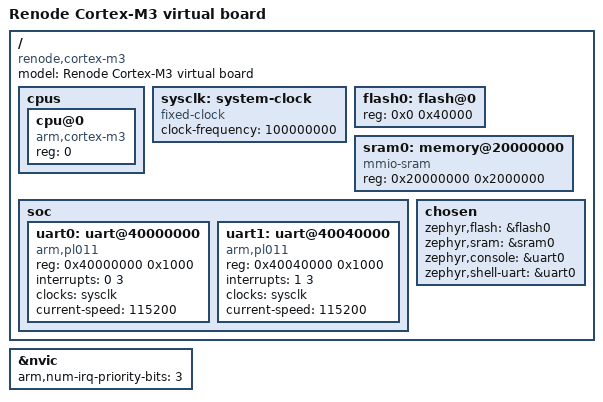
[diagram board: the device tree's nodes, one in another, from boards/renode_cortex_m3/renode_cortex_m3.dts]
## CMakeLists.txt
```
#
# Host application for the embedded80211 link protocol (Renode board profile).
#
# Runs on the app-local renode_cortex_m33 board (see boards/renode_cortex_m33/).
# uart1 is the bus port bridged to the device; uart0 is the console. The
# virtual Wi-Fi and BT HCI drivers are registered in app.overlay.
#
cmake_minimum_required(VERSION 3.20.5)
cmake_policy(SET CMP0057 NEW)

# Register the embedded80211 Zephyr module (sibling directory). Must be set
# before find_package(Zephyr) so the module is discovered during kernel-mode
# build configuration (mirrors nrf7002dk/CMakeLists.txt).
set(ZEPHYR_EXTRA_MODULES ${CMAKE_CURRENT_SOURCE_DIR}/../embedded80211)

# App-local board and SoC definitions. Prepend this directory to BOARD_ROOT
# and SOC_ROOT so `west build -b renode_cortex_m3` finds them without
# extra flags.
set(BOARD_ROOT ${CMAKE_CURRENT_SOURCE_DIR} ${BOARD_ROOT})
set(SOC_ROOT ${CMAKE_CURRENT_SOURCE_DIR} ${SOC_ROOT})

find_package(Zephyr REQUIRED HINTS $ENV{ZEPHYR_BASE})
project(e80211_host)
# Expose the embedded80211 module public headers to the app sources.
target_include_directories(app PUBLIC
	${CMAKE_CURRENT_SOURCE_DIR}/../embedded80211/zephyr/include
)

target_sources(app PRIVATE src/main.c)

if(CONFIG_HOST_TEST_ENABLED)
	target_sources(app PRIVATE src/e2e_test.c src/bt_e2e.c)
endif()
```

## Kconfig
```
source "Kconfig.zephyr"

# Host application options.
# The embedded80211 module Kconfig is sourced automatically when the module
# is registered via ZEPHYR_EXTRA_MODULES (see CMakeLists.txt).

# E2E test (disabled by default). When enabled, src/e2e_test.c is compiled in
# and e2e_test_start() is called from main(); WiFi credentials come from
# HOST_TEST_WIFI_SSID / HOST_TEST_WIFI_PSK (build-time, never committed).
config HOST_TEST_ENABLED
	bool "Enable end-to-end test"
	default n
	depends on EMBEDDED80211_HOST_WIFI
	depends on EMBEDDED80211_HOST_BT
config HOST_TEST_WIFI_SSID
	string "E2E test SSID (empty = skip WiFi E2E)"
	default ""

config HOST_TEST_WIFI_PSK
	string "E2E test PSK"
	default ""

config HOST_TEST_GATEWAY_PINGS
	int "Gateway ping count"
	default 4
```

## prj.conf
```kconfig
# Role: host driver.
CONFIG_SERIAL_HOST_ROLE=y
CONFIG_SERIAL=y
CONFIG_UART_INTERRUPT_DRIVEN=y


# embedded80211 host drivers.
CONFIG_EMBEDDED80211_HOST_BUS=y
CONFIG_EMBEDDED80211_HOST_WIFI=y
CONFIG_EMBEDDED80211_HOST_BT=y

# Networking (virtual Wi-Fi).
CONFIG_NETWORKING=y
CONFIG_NET_L2_ETHERNET=y
CONFIG_NET_L2_WIFI_MGMT=y
CONFIG_NET_MGMT_EVENT=y
CONFIG_NET_MGMT_EVENT_INFO=y
CONFIG_WIFI=y
CONFIG_NET_IPV4=y
CONFIG_NET_DHCPV4=y
CONFIG_NET_DHCPV4_LOG_LEVEL_DBG=y
CONFIG_NET_UDP=y
CONFIG_NET_LOG=y
CONFIG_NET_BUF_RX_COUNT=256
CONFIG_NET_BUF_TX_COUNT=64
CONFIG_NET_PKT_RX_COUNT=128
CONFIG_NET_PKT_TX_COUNT=64
# Accept broadcast L2 frames with L3 dst not yet matching the interface
# broadcast (needed before DHCP assigns an address).
CONFIG_NET_L2_ETHERNET_ACCEPT_MISMATCH_L3_L2_ADDR=y
CONFIG_HEAP_MEM_POOL_SIZE=8192

# Bluetooth (virtual HCI).
CONFIG_BT=y
CONFIG_BT_HCI=y
CONFIG_BT_OBSERVER=y
CONFIG_BT_DEVICE_NAME="e80211-host"

# Logging / console.
CONFIG_LOG=y
CONFIG_CONSOLE=y

# The bus client's sync handshake (bus_open -> bus_sync) needs more than the
# 1024 B default main stack; a smaller stack overflows and faults at boot.
# 4096 and 8192 were both insufficient with the full net+BT subsystem;
# the init path (net_if + DHCP + BT controller) consumes ~8 KB of stack.
CONFIG_MAIN_STACK_SIZE=16384

# The network stack's RX processing (net_if_recv_data -> DHCP -> ARP) runs
# on the system workqueue; the default 1024 B overflows and stalls RX,
# exhausting the net_buf pool.
CONFIG_SYSTEM_WORKQUEUE_STACK_SIZE=4096

# CRC32C for the link-protocol integrity feature (bus.c / serial_frame_crc).
CONFIG_CRC=y
CONFIG_CRC32_C=y
```

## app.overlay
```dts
/ {
	chosen {
		zephyr,bt-hci = &bt_hci_virt;
		embedded80211,bus = &uart1;
	};

	virt_wifi: virt-wifi {
		compatible = "embedded80211,virt-wifi";
	};

	bt_hci_virt: bt-hci-virtual {
		compatible = "embedded80211,bt-hci-virtual";
	};
};

&uart1 {
	status = "okay";
	current-speed = <115200>;
};
```

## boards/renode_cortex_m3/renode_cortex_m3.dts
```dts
/*
 * Renode virtual Cortex-M3 board for the host application.
 *
 * The peripheral map must stay in sync with the Renode machine definition
 * in support/renode_cortex_m3.repl:
 *   ROM   256 KiB @ 0x0
 *   RAM   32 MiB @ 0x20000000
 *   CPU   Cortex-M3 @ 100 MHz (systick)
 *   uart0 console  arm,pl011 @ 0x40000000  IRQ 0
 *   uart1 bus      arm,pl011 @ 0x40040000  IRQ 1
 *
 * Code is linked into the 256 KiB `flash0` region at 0x0 (Renode `rom`);
 * data lives in the 32 MiB SRAM at 0x20000000.
 */

/dts-v1/;

#include <arm/armv7-m.dtsi>

/ {
	#address-cells = <1>;
	#size-cells = <1>;
	compatible = "renode,cortex-m3";
	model = "Renode Cortex-M3 virtual board";

	cpus {
		#address-cells = <1>;
		#size-cells = <0>;
		cpu@0 {
			device_type = "cpu";
			compatible = "arm,cortex-m3";
			reg = <0>;
		};
	};

	sysclk: system-clock {
		compatible = "fixed-clock";
		clock-frequency = <100000000>;
		#clock-cells = <0>;
	};

	/* Code segment: Renode maps a writable 256 KiB region at 0x0
	 * (rom in support/renode_cortex_m3.repl); `loadelf` populates it. */
	flash0: flash@0 {
		reg = <0x0 0x40000>;
	};

	sram0: memory@20000000 {
		compatible = "mmio-sram";
		reg = <0x20000000 0x2000000>;
	};

	soc {
		#address-cells = <1>;
		#size-cells = <1>;
		ranges;

		uart0: uart@40000000 {
			compatible = "arm,pl011";
			reg = <0x40000000 0x1000>;
			interrupts = <0 3>;
			interrupt-names = "uart";
			clocks = <&sysclk>;
		};

		uart1: uart@40040000 {
			compatible = "arm,pl011";
			reg = <0x40040000 0x1000>;
			interrupts = <1 3>;
			interrupt-names = "uart";
			clocks = <&sysclk>;
		};
	};

	chosen {
		zephyr,flash = &flash0;
		zephyr,sram = &sram0;
		zephyr,console = &uart0;
		zephyr,shell-uart = &uart0;
	};
};

&uart0 {
	status = "okay";
	current-speed = <115200>;
};

&uart1 {
	status = "okay";
	current-speed = <115200>;
};

&nvic {
	arm,num-irq-priority-bits = <3>;
};
```

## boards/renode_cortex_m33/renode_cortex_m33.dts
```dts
/*
 * Renode virtual Cortex-M33 board for the host application.
 *
 * The peripheral map must stay in sync with the Renode machine definition
 * in support/renode_cortex_m33.repl:
 *   ROM   256 KiB @ 0x0
 *   RAM   32 MiB @ 0x20000000
 *   CPU   Cortex-M33 @ 100 MHz (systick)
 *   uart0 console  arm,pl011 @ 0x40000000  IRQ 0
 *   uart1 bus      arm,pl011 @ 0x40040000  IRQ 1
 *
 * Code is linked into the 256 KiB `flash0` region at 0x0 (Renode `rom`);
 * data lives in the 32 MiB SRAM at 0x20000000.
 */

/dts-v1/;

#include <arm/armv8-m.dtsi>

/ {
	#address-cells = <1>;
	#size-cells = <1>;
	compatible = "renode,cortex-m33";
	model = "Renode Cortex-M33 virtual board";

	cpus {
		#address-cells = <1>;
		#size-cells = <0>;
		cpu@0 {
			device_type = "cpu";
			compatible = "arm,cortex-m33";
			reg = <0>;
		};
	};

	sysclk: system-clock {
		compatible = "fixed-clock";
		clock-frequency = <100000000>;
		#clock-cells = <0>;
	};


	/* Code segment: Renode maps a writable 256 KiB region at 0x0
	 * (rom in support/renode_cortex_m33.repl); `loadelf` populates it. */
	flash0: flash@0 {
		reg = <0x0 0x40000>;
	};

	sram0: memory@20000000 {
		compatible = "mmio-sram";
		reg = <0x20000000 0x2000000>;
	};

	soc {
		#address-cells = <1>;
		#size-cells = <1>;
		ranges;

		uart0: uart@40000000 {
			compatible = "arm,pl011";
			reg = <0x40000000 0x1000>;
			interrupts = <0 3>;
			interrupt-names = "uart";
			clocks = <&sysclk>;
		};

		uart1: uart@40040000 {
			compatible = "arm,pl011";
			reg = <0x40040000 0x1000>;
			interrupts = <1 3>;
			interrupt-names = "uart";
			clocks = <&sysclk>;
		};
	};

	chosen {
		zephyr,flash = &flash0;
		zephyr,sram = &sram0;
		zephyr,console = &uart0;
		zephyr,shell-uart = &uart0;
	};
};

&uart0 {
	status = "okay";
	current-speed = <115200>;
};

&uart1 {
	status = "okay";
	current-speed = <115200>;
};

&nvic {
	arm,num-irq-priority-bits = <3>;
};
```

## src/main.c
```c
/*
 * Host application entry point (Renode board profile).
 *
 * Boots the virtual Wi-Fi / BT HCI drivers (registered via app.overlay),
 * opens the link-protocol bus to the device, and starts the E2E test threads.
 */

#include <zephyr/kernel.h>
#include <zephyr/logging/log.h>

#include <embedded80211/bus.h>

#if CONFIG_HOST_TEST_ENABLED
#include "e2e_test.h"
#include "bt_e2e.h"
#endif

LOG_MODULE_REGISTER(e80211_host, LOG_LEVEL_INF);

int main(void)
{
	LOG_INF("e80211 host app booting");

	int rc = bus_open();

	if (rc != 0) {
		LOG_ERR("bus_open failed: %d", rc);
	} else {
		LOG_INF("bus synced: supported types 0x%04x",
			bus_supported_types());
	}

#if CONFIG_HOST_TEST_ENABLED
	e2e_test_start();
	bt_e2e_start();
#endif

	return 0;
}
```

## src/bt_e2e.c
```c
/*
 * E2E Bluetooth test for the host app.
 *
 * Periodic BLE scan window, logging discovered devices.
 *
 * Log marker (consumed by host/tests/run_e2e.sh):
 *   E2E BT:  SCAN DONE found=<n>
 */

#include <zephyr/kernel.h>
#include <zephyr/logging/log.h>
#include <zephyr/bluetooth/bluetooth.h>
#include <zephyr/bluetooth/addr.h>

#include "bt_e2e.h"
#include "e2e_test.h"

LOG_MODULE_REGISTER(e80211_e2e_bt, LOG_LEVEL_INF);

#define BT_SCAN_WINDOW_S  10U
#define BT_SCAN_PERIOD_S  30U

static int bt_found_count;

static void bt_adv_cb(const bt_addr_le_t *addr, int8_t rssi,
		      uint8_t adv_type, struct net_buf_simple *buf)
{
	char addr_str[BT_ADDR_LE_STR_LEN];

	bt_addr_le_to_str(addr, addr_str, sizeof(addr_str));
	bt_found_count++;
	LOG_INF("E2E BT: DEV %s rssi=%d", addr_str, rssi);
}

static const struct bt_le_scan_param scan_params[] = BT_LE_SCAN_ACTIVE;

static void bt_e2e_thread(void *p1, void *p2, void *p3)
{
	ARG_UNUSED(p1);
	ARG_UNUSED(p2);
	ARG_UNUSED(p3);
	/* Wait for the Wi-Fi connect phase to finish before touching the
	 * BT controller. The nRF7002 shares one IPC link for Wi-Fi and
	 * BT; concurrent HCI and Wi-Fi management commands cause HCI
	 * command timeouts and a fatal assertion. e2e_wait_wifi_phase()
	 * releases once step 2 (connect) has completed, success or
	 * failure; the 40 s bound covers the 30 s connect timeout plus
	 * margin so a wedged connect cannot stall the BT phase forever.
	 */
	e2e_wait_wifi_phase(40000);

	/* Bring up the BT controller, then wait for it to be ready. */
	int err = bt_enable(NULL);

	if (err < 0) {
		LOG_ERR("E2E BT: enable failed: %d", err);
		return;
	}

	while (!bt_is_ready()) {
		k_sleep(K_SECONDS(1));
	}
	LOG_INF("E2E BT: controller ready");


	/* Single scan window: start, collect results, log. The stop
	 * command (LE_Set_Scan_Enable 0x200c disable) times out on the
	 * nRF7002 controller over the IPC link, triggering a fatal HCI
	 * assertion. The scan window is the E2E criterion; stopping the
	 * scanner is not.
	 */
	bt_found_count = 0;
	int rc = bt_le_scan_start(scan_params, bt_adv_cb);

	if (rc != 0) {
		LOG_ERR("E2E BT: scan start failed: %d", rc);
		return;
	}

	k_sleep(K_SECONDS(BT_SCAN_WINDOW_S));
	LOG_INF("E2E BT: SCAN DONE found=%d", bt_found_count);
}

K_THREAD_STACK_DEFINE(bt_stack, 2048);
static struct k_thread bt_thread;

void bt_e2e_start(void)
{
	k_thread_create(&bt_thread, bt_stack,
			K_THREAD_STACK_SIZEOF(bt_stack),
			bt_e2e_thread, NULL, NULL, NULL,
			K_PRIO_COOP(8), 0, K_NO_WAIT);
	k_thread_name_set(&bt_thread, "bt_e2e");
}
```

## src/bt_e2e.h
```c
/*
 * E2E Bluetooth test for the host app.
 *
 * Periodic BLE scan window, logging discovered devices.
 *
 * Log marker (consumed by host/tests/run_e2e.sh):
 *   E2E BT:  SCAN DONE found=<n>
 */

#ifndef E80211_HOST_BT_E2E_H
#define E80211_HOST_BT_E2E_H

void bt_e2e_start(void);

#endif /* E80211_HOST_BT_E2E_H */
```

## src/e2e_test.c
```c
/*
 * E2E network integration test for the host app.
 *
 * Brings up IPv4 over Wi-Fi and verifies the full path, in order:
 *   1. Print the interface MTU and MAC address.
 *   2. Connect to the AP (SSID/PSK from Kconfig, build-time only) via
 *      NET_REQUEST_WIFI_CONNECT; the result arrives as a net_mgmt event.
 *   3. Bring the interface up and start the DHCPv4 client; wait for the
 *      DHCP BOUND management event.
 *   4. Print the assigned IPv4 address, netmask, gateway and lease info.
 *   5. Ping the default gateway CONFIG_HOST_TEST_GATEWAY_PINGS times;
 *      print each reply (sequence, source, RTT) and a summary. The test
 *      passes when every packet gets an echo reply.
 *
 * The Bluetooth E2E part lives in bt_e2e.c.
 *
 * Every step prints a structured "E2E WIFI:" status line; a failure
 * prints "E2E WIFI: FAIL step=<n> reason=<...>" and stops the test.
 *
 * Log markers (consumed by host/tests/run_e2e.sh):
 *   E2E WIFI: CONNECTED
 *   E2E WIFI: DHCP BOUND
 *   E2E WIFI: PING SUMMARY
 *   E2E WIFI: OK
 */

#include <zephyr/kernel.h>
#include <zephyr/logging/log.h>
#include <zephyr/net/net_if.h>
#include <zephyr/net/net_mgmt.h>
#include <zephyr/net/wifi_mgmt.h>
#include <zephyr/net/icmp.h>
#include <zephyr/net/dhcpv4.h>
#include <zephyr/net/net_ip.h>
#include <string.h>

LOG_MODULE_REGISTER(e80211_e2e, LOG_LEVEL_INF);

#define CONNECT_TIMEOUT_MS  30000U
#define DHCP_TIMEOUT_S      30U
#define PING_TIMEOUT_S      5U

/* Resolve the virtual Wi-Fi interface by type, not by index: an interface
 * index is an allocation order and is only stable when virt_wifi is the
 * sole non-loopback interface. */
static void find_wifi_iface_cb(struct net_if *iface, void *user)
{
	struct net_if **found = user;

	if (*found == NULL && net_if_is_wifi(iface)) {
		*found = iface;
	}
}

static struct net_if *wifi_iface;
static struct net_mgmt_event_callback mgmt_cb;
static K_SEM_DEFINE(connect_sem, 0, 1);
static K_SEM_DEFINE(dhcp_sem, 0, 1);
static K_SEM_DEFINE(ping_sem, 0, 1);
/* Given once the Wi-Fi connect phase (step 2) has finished, success or
 * failure. The BT thread waits on this before touching the controller so
 * HCI and Wi-Fi management never contend for the nRF7002 IPC link. */
static K_SEM_DEFINE(wifi_phase_sem, 0, 1);
static struct net_icmp_ctx ping_ctx;
static int connect_status = -1;
static int64_t ping_t0;

static void sprint_ipv4(const struct net_in_addr *addr, char *buf, size_t size)
{
	snprintf(buf, size, "%u.%u.%u.%u",
		 addr->s4_addr[0], addr->s4_addr[1],
		 addr->s4_addr[2], addr->s4_addr[3]);
}

static void e2e_fail(int step, const char *reason, int rc)
{
	LOG_ERR("E2E WIFI: FAIL step=%d reason=%s (%d)", step, reason, rc);
}

/* Step 1: print the interface MTU and MAC address. */
static int step1_iface_info(void)
{
	const struct net_linkaddr *mac = &wifi_iface->if_dev->link_addr;
	char mac_str[18] = "?";

	if (mac->len == 6) {
		snprintf(mac_str, sizeof(mac_str), "%02x:%02x:%02x:%02x:%02x:%02x",
			 mac->addr[0], mac->addr[1], mac->addr[2],
			 mac->addr[3], mac->addr[4], mac->addr[5]);
	}

	LOG_INF("E2E WIFI: STEP 1 IFACE index=%d mtu=%d mac=%s",
		net_if_get_by_iface(wifi_iface), net_if_get_mtu(wifi_iface),
		mac_str);
	return 0;
}

static void net_mgmt_handler(struct net_mgmt_event_callback *cb,
			     uint64_t mgmt_event, struct net_if *iface)
{
	if (iface != NULL && iface != wifi_iface) {
		return;
	}

	switch (mgmt_event) {
	case NET_EVENT_WIFI_CONNECT_RESULT: {
		const int *status = cb->info;

		connect_status = (status != NULL) ? *status : -1;
		k_sem_give(&connect_sem);
		break;
	}
	case NET_EVENT_IPV4_DHCP_BOUND:
	case NET_EVENT_IPV4_CMD_DHCP_BOUND:
		k_sem_give(&dhcp_sem);
		break;
	default:
		break;
	}
}

static uint64_t e2e_event_mask(void)
{
	return NET_EVENT_WIFI_CONNECT_RESULT |
	       NET_EVENT_IPV4_DHCP_BOUND |
	       NET_EVENT_IPV4_CMD_DHCP_BOUND;
}

/* Step 2: connect to the AP and wait for the connect result event. */
static int step2_connect(void)
{
	struct wifi_connect_req_params params = {
		.ssid = (const uint8_t *)CONFIG_HOST_TEST_WIFI_SSID,
		.ssid_length = sizeof(CONFIG_HOST_TEST_WIFI_SSID) - 1,
		.psk = (const uint8_t *)CONFIG_HOST_TEST_WIFI_PSK,
		.psk_length = sizeof(CONFIG_HOST_TEST_WIFI_PSK) - 1,
		.security = (CONFIG_HOST_TEST_WIFI_PSK[0] == '\0') ?
				WIFI_SECURITY_TYPE_NONE : WIFI_SECURITY_TYPE_PSK,
		.channel = WIFI_CHANNEL_ANY,
		.band = WIFI_FREQ_BAND_2_4_GHZ,
	};
	int rc;

	rc = net_mgmt(NET_REQUEST_WIFI_CONNECT, wifi_iface, &params,
		      sizeof(params));
	if (rc != 0) {
		e2e_fail(2, "connect start", rc);
		return rc;
	}

	if (k_sem_take(&connect_sem, K_MSEC(CONNECT_TIMEOUT_MS)) != 0) {
		e2e_fail(2, "connect timeout", -ETIMEDOUT);
		return -ETIMEDOUT;
	}

	if (connect_status != 0) {
		e2e_fail(2, "connect rejected", connect_status);
		return connect_status;
	}

	LOG_INF("E2E WIFI: CONNECTED ssid=%s", CONFIG_HOST_TEST_WIFI_SSID);
	return 0;
}

/* Step 3: bring the interface up and wait for the DHCP lease. */
static int step3_dhcp(void)
{
	/* Set NET_IF_UP and NET_IF_RUNNING directly. net_if_up() is
	 * broken for Wi-Fi offload devices (ethernet_enable type-puns
	 * dev->api). net_if_is_up() requires BOTH flags.
	 */
	net_if_flag_set(wifi_iface, NET_IF_UP);
	net_if_flag_set(wifi_iface, NET_IF_RUNNING);
	LOG_INF("E2E WIFI: IFACE UP (is_up=%d)", net_if_is_up(wifi_iface));

	net_dhcpv4_start(wifi_iface);

	if (k_sem_take(&dhcp_sem, K_SECONDS(DHCP_TIMEOUT_S)) != 0) {
		e2e_fail(3, "dhcp timeout", -ETIMEDOUT);
		return -ETIMEDOUT;
	}

	return 0;
}

/* Step 4: query and print the assigned IPv4 configuration. */
static int step4_print_config(char *gw_str, size_t gw_size,
			      struct net_in_addr *gw)
{
	struct net_in_addr *addr;
	struct net_in_addr mask;
	char ip[16];
	char mask_str[16];

	addr = net_if_ipv4_get_global_addr(wifi_iface, NET_ADDR_PREFERRED);
	if (addr == NULL) {
		e2e_fail(4, "no global ipv4 address", -ENOENT);
		return -ENOENT;
	}

	mask = net_if_ipv4_get_netmask_by_addr(wifi_iface, addr);
	*gw = net_if_ipv4_get_gw(wifi_iface);
	if (gw->s4_addr[0] == 0) {
		e2e_fail(4, "no default gateway", -ENOENT);
		return -ENOENT;
	}

	sprint_ipv4(addr, ip, sizeof(ip));
	sprint_ipv4(&mask, mask_str, sizeof(mask_str));
	sprint_ipv4(gw, gw_str, gw_size);

	LOG_INF("E2E WIFI: DHCP BOUND ip=%s mask=%s gw=%s lease=%us",
		ip, mask_str, gw_str, wifi_iface->config.dhcpv4.lease_time);
	return 0;
}

static enum net_verdict ping_reply_handler(struct net_icmp_ctx *ctx,
					   struct net_pkt *pkt,
					   struct net_icmp_ip_hdr *ip_hdr,
					   struct net_icmp_hdr *icmp_hdr,
					   void *user_data)
{
	const uint8_t *echo;
	uint16_t seq;

	ARG_UNUSED(ctx);
	ARG_UNUSED(pkt);

	/* The echo id/seq follow the 4-byte ICMP header on the wire; the
	 * Zephyr net_icmp_hdr struct does not carry them. Wire order is
	 * big-endian: id at offset 0..1, seq at offset 2..3.
	 */
	echo = (const uint8_t *)icmp_hdr + sizeof(struct net_icmp_hdr);
	seq = (uint16_t)echo[2] | ((uint16_t)echo[3] << 8);

	LOG_INF("E2E WIFI: PING RECV seq=%d from %u.%u.%u.%u rtt=%lldms",
		seq,
		ip_hdr->ipv4->src[0],
		ip_hdr->ipv4->src[1],
		ip_hdr->ipv4->src[2],
		ip_hdr->ipv4->src[3],
		(long long)(k_uptime_get() - *(int64_t *)user_data));
	k_sem_give(&ping_sem);
	return NET_OK;
}

/* Step 5: ping the gateway, print per-packet RTT and a summary.
 * Returns 0 when every packet got a reply.
 */
static int step5_ping(const struct net_in_addr *gw)
{
	union {
		struct net_sockaddr_in dst4;
		struct net_sockaddr dst;
	} daddr;
	char gw_str[16];
	int count = CONFIG_HOST_TEST_GATEWAY_PINGS;
	int sent = 0;
	int recv = 0;
	int64_t rtt_min = INT64_MAX;
	int64_t rtt_max = 0;
	int64_t rtt_sum = 0;
	int rc;

	sprint_ipv4(gw, gw_str, sizeof(gw_str));
	LOG_INF("E2E WIFI: STEP 5 PING gw=%s count=%d", gw_str, count);

	net_icmp_init_ctx(&ping_ctx, AF_INET, NET_ICMPV4_ECHO_REPLY, 0,
			  ping_reply_handler);
	ping_ctx.user_data = &ping_t0;
	daddr.dst4.sin_family = AF_INET;
	daddr.dst4.sin_addr = *gw;

	for (int i = 0; i < count; i++) {
		rc = net_icmp_send_echo_request(&ping_ctx, wifi_iface,
						&daddr.dst, NULL, NULL);
		if (rc != 0) {
			e2e_fail(5, "ping send", rc);
			break;
		}
		sent++;
		ping_t0 = k_uptime_get();

		if (k_sem_take(&ping_sem, K_SECONDS(PING_TIMEOUT_S)) == 0) {
			int64_t rtt = k_uptime_get() - ping_t0;

			recv++;
			rtt_min = MIN(rtt_min, rtt);
			rtt_max = MAX(rtt_max, rtt);
			rtt_sum += rtt;
		}
	}

	net_icmp_cleanup_ctx(&ping_ctx);

	if (recv > 0) {
		LOG_INF("E2E WIFI: PING SUMMARY sent=%d recv=%d loss=%d%% "
			"min=%lldms avg=%lldms max=%lldms",
			sent, recv, (sent - recv) * 100 / sent,
			(long long)rtt_min, (long long)(rtt_sum / recv),
			(long long)rtt_max);
	} else {
		LOG_INF("E2E WIFI: PING SUMMARY sent=%d recv=%d loss=100%%",
			sent, recv);
	}

	if (sent == 0 || recv != sent) {
		e2e_fail(5, "ping loss", recv - sent);
		return -EIO;
	}

	return 0;
}

static void e2e_thread(void *p1, void *p2, void *p3)
{
	ARG_UNUSED(p1);
	ARG_UNUSED(p2);
	ARG_UNUSED(p3);

	if (CONFIG_HOST_TEST_WIFI_SSID[0] == '\0') {
		LOG_INF("E2E WIFI: SKIPPED (no SSID configured)");
		return;
	}

	net_if_foreach(find_wifi_iface_cb, &wifi_iface);
	if (wifi_iface == NULL) {
		e2e_fail(1, "no wifi interface", -ENOENT);
		return;
	}

	if (step1_iface_info() != 0) {
		return;
	}

	int rc2 = step2_connect();

	/* Release the BT thread: the connect phase is over (success or
	 * failure), so HCI and Wi-Fi management no longer contend. */
	k_sem_give(&wifi_phase_sem);

	if (rc2 != 0) {
		return;
	}

	if (step3_dhcp() != 0) {
		return;
	}

	char gw_str[16];
	struct net_in_addr gw;

	if (step4_print_config(gw_str, sizeof(gw_str), &gw) != 0) {
		return;
	}

	if (step5_ping(&gw) != 0) {
		return;
	}

	LOG_INF("E2E WIFI: OK");
}

K_THREAD_STACK_DEFINE(e2e_stack, 4096);
static struct k_thread e2e_thread_obj;

void e2e_test_start(void)
{
	net_mgmt_init_event_callback(&mgmt_cb, net_mgmt_handler,
				    e2e_event_mask());
	net_mgmt_add_event_callback(&mgmt_cb);

	k_thread_create(&e2e_thread_obj, e2e_stack,
			K_THREAD_STACK_SIZEOF(e2e_stack),
			e2e_thread, NULL, NULL, NULL,
			K_PRIO_COOP(7), 0, K_NO_WAIT);
	k_thread_name_set(&e2e_thread_obj, "wifi_e2e");
}

/* Block until the Wi-Fi connect phase has finished (or the timeout
 * elapses). Called by the BT thread so it never starts the controller
 * while the nRF7002 is mid-association. */
void e2e_wait_wifi_phase(uint32_t timeout_ms)
{
	(void)k_sem_take(&wifi_phase_sem, K_MSEC(timeout_ms));
}
```

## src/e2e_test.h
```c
/*
 * E2E network integration test for the host app.
 *
 * Brings up IPv4 over Wi-Fi (SSID/PSK from Kconfig, build-time only):
 * interface info, connect, DHCP, print the assigned configuration,
 * ping the default gateway and report a pass/fail summary.
 *
 * The Bluetooth E2E part is in bt_e2e.h/bt_e2e.c.
 *
 * Log markers (consumed by host/tests/run_e2e.sh):
 *   E2E WIFI: CONNECTED
 *   E2E WIFI: DHCP BOUND
 *   E2E WIFI: PING SUMMARY
 *   E2E WIFI: OK
 */

#ifndef E80211_HOST_E2E_TEST_H
#define E80211_HOST_E2E_TEST_H

void e2e_test_start(void);

/* Block until the Wi-Fi connect phase (step 2) has finished, or
 * timeout_ms elapses. Lets the BT thread start the controller only after
 * the nRF7002 has finished associating, avoiding IPC-link contention. */
void e2e_wait_wifi_phase(uint32_t timeout_ms);

#endif /* E80211_HOST_E2E_TEST_H */
```
